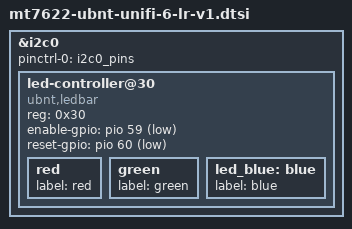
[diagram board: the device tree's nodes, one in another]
#include "mt7622-ubnt-unifi-6-lr.dtsi"

&i2c0 {
	pinctrl-names = "default";
	pinctrl-0 = <&i2c0_pins>;
	status = "okay";

	led-controller@30 {
		compatible = "ubnt,ledbar";
		reg = <0x30>;

		enable-gpio = <&pio 59 GPIO_ACTIVE_LOW>;
		reset-gpio = <&pio 60 GPIO_ACTIVE_LOW>;

		red {
			label = "red";
		};

		green {
			label = "green";
		};

		led_blue: blue {
			label = "blue";
		};
	};
};

